# MK70F15WS register map
File version: 1.6
Registers are 32-bit, read-write, reset 0x0 unless marked. A register's access mark holds for its fields unless they carry their own. Offsets are from the block's base; [hi:lo] are bit positions; {n}, {i} and the like mark numbered series; 'fields as' and 'values as' point back to an identical list.

## CAU — Memory Mapped Cryptographic Acceleration Unit (MMCAU)
Base 0xE0081000
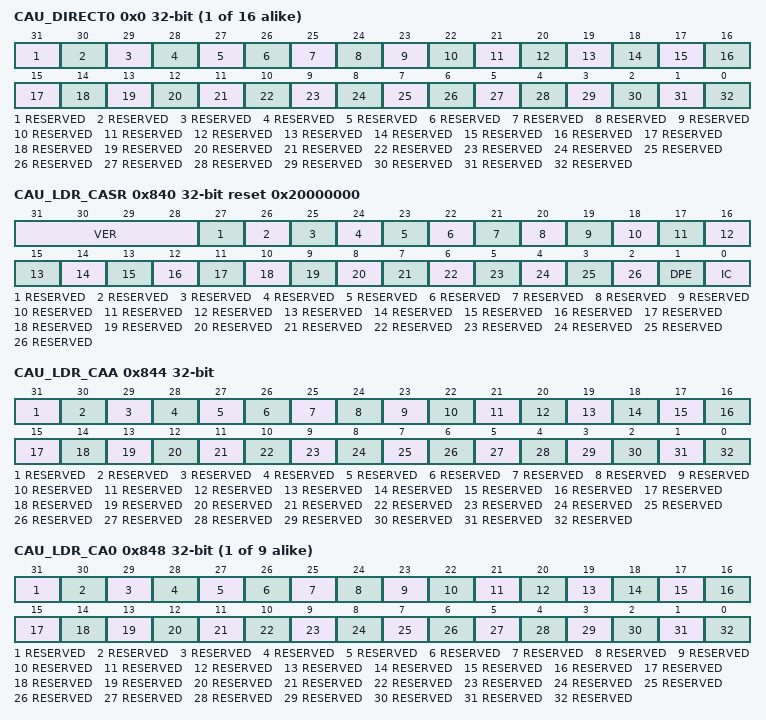
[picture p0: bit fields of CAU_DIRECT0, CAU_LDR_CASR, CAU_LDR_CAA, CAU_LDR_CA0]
{0x0+4i} CAU_DIRECT{i} wo (i=0..15) — Direct access register {i}
  [31] RESERVED, [30] RESERVED, [29] RESERVED, [28] RESERVED, [27] RESERVED, [26] RESERVED, [25] RESERVED, [24] RESERVED, [23] RESERVED, [22] RESERVED, [21] RESERVED, [20] RESERVED, [19] RESERVED, [18] RESERVED, [17] RESERVED, [16] RESERVED, [15] RESERVED, [14] RESERVED, [13] RESERVED, [12] RESERVED, [11] RESERVED, [10] RESERVED, [9] RESERVED, [8] RESERVED, [7] RESERVED, [6] RESERVED, [5] RESERVED, [4] RESERVED, [3] RESERVED, [2] RESERVED, [1] RESERVED, [0] RESERVED
0x840 CAU_LDR_CASR wo reset 0x20000000 — Status register - Load Register command
  [31:28] VER — CAU version
    1=Initial CAU version; 2=Second version, added support for SHA-256 algorithm.(This is the value on this device)
  [27] RESERVED
  [26] RESERVED
  [25] RESERVED
  [24] RESERVED
  [23] RESERVED
  [22] RESERVED
  [21] RESERVED
  [20] RESERVED
  [19] RESERVED
  [18] RESERVED
  [17] RESERVED
  [16] RESERVED
  [15] RESERVED
  [14] RESERVED
  [13] RESERVED
  [12] RESERVED
  [11] RESERVED
  [10] RESERVED
  [9] RESERVED
  [8] RESERVED
  [7] RESERVED
  [6] RESERVED
  [5] RESERVED
  [4] RESERVED
  [3] RESERVED
  [2] RESERVED
  [1] DPE
    0=No error detected; 1=DES key parity error detected
  [0] IC
    0=No illegal commands issued; 1=Illegal command issued
0x844 CAU_LDR_CAA wo — Accumulator register - Load Register command
  fields as CAU_DIRECT0
{0x848+4i} CAU_LDR_CA{i} wo (i=0..8) — General Purpose Register {i} - Load Register command
  fields as CAU_DIRECT0
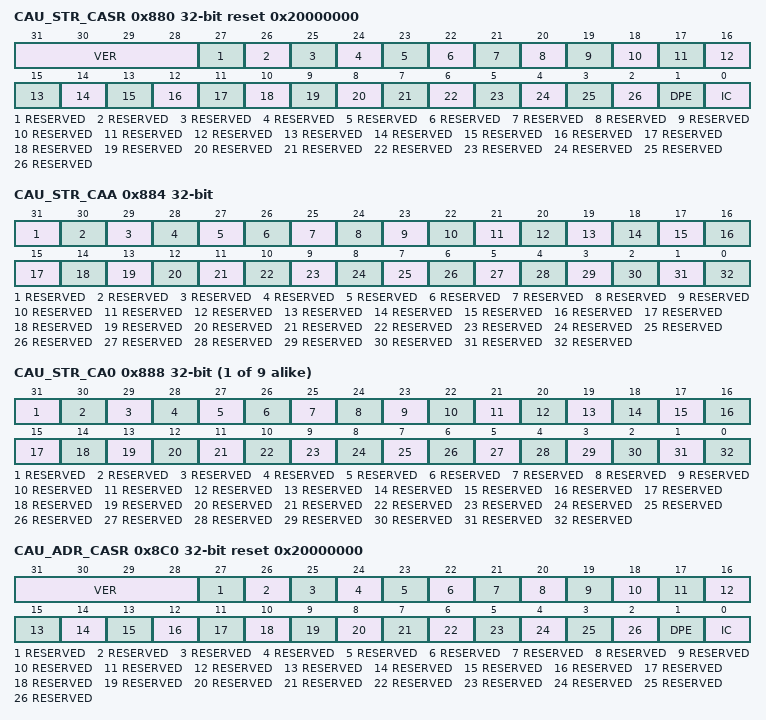
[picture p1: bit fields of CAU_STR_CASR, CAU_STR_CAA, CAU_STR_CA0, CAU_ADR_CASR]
0x880 CAU_STR_CASR ro reset 0x20000000 — Status register - Store Register command
  fields as CAU_LDR_CASR
0x884 CAU_STR_CAA ro — Accumulator register - Store Register command
  fields as CAU_DIRECT0
{0x888+4i} CAU_STR_CA{i} ro (i=0..8) — General Purpose Register {i} - Store Register command
  fields as CAU_DIRECT0
0x8C0 CAU_ADR_CASR wo reset 0x20000000 — Status register - Add Register command
  fields as CAU_LDR_CASR
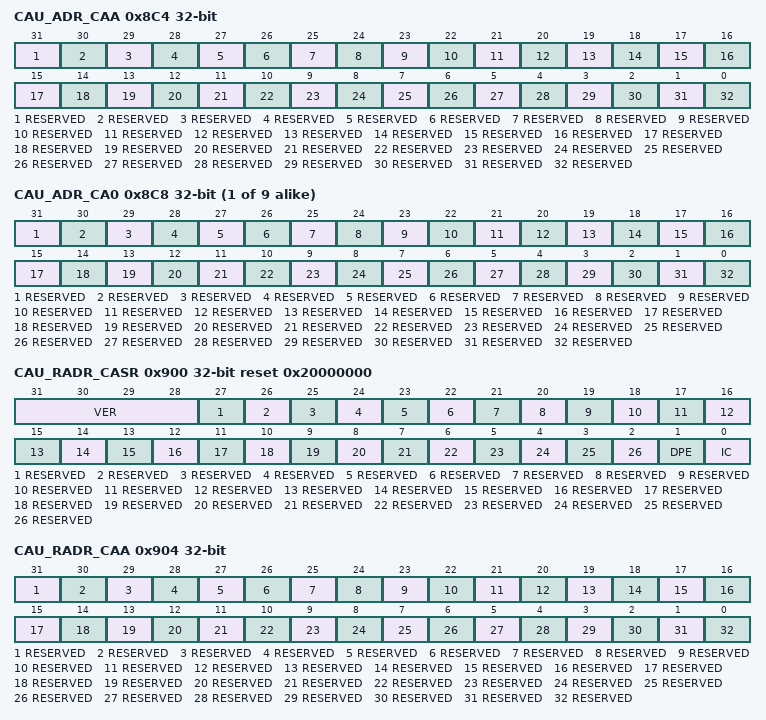
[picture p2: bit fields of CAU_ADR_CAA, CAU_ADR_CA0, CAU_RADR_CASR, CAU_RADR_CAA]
0x8C4 CAU_ADR_CAA wo — Accumulator register - Add to register command
  fields as CAU_DIRECT0
{0x8C8+4i} CAU_ADR_CA{i} wo (i=0..8) — General Purpose Register {i} - Add to register command
  fields as CAU_DIRECT0
0x900 CAU_RADR_CASR wo reset 0x20000000 — Status register - Reverse and Add to Register command
  fields as CAU_LDR_CASR
0x904 CAU_RADR_CAA wo — Accumulator register - Reverse and Add to Register command
  fields as CAU_DIRECT0
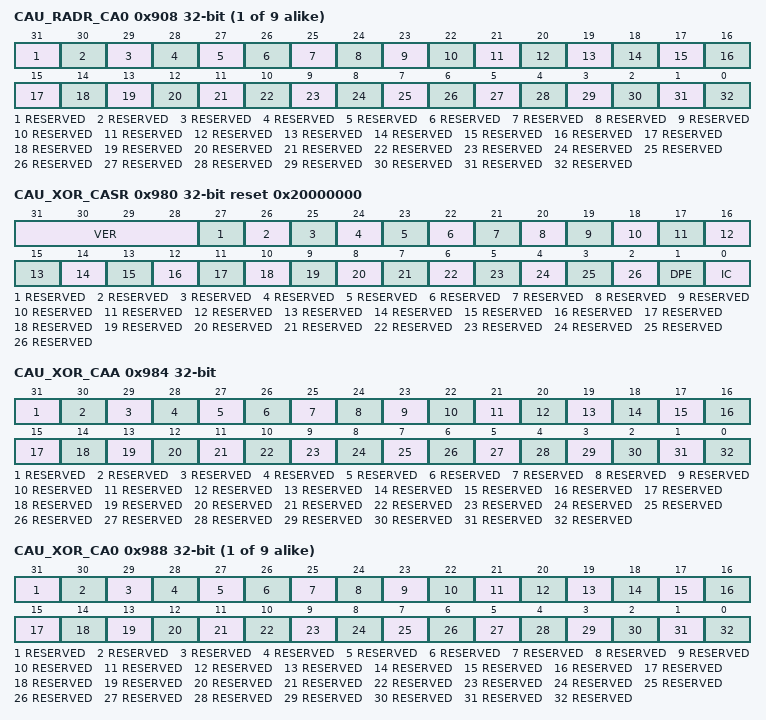
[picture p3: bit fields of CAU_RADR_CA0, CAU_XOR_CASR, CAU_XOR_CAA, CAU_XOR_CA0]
{0x908+4i} CAU_RADR_CA{i} wo (i=0..8) — General Purpose Register {i} - Reverse and Add to Register command
  fields as CAU_DIRECT0
0x980 CAU_XOR_CASR wo reset 0x20000000 — Status register - Exclusive Or command
  fields as CAU_LDR_CASR
0x984 CAU_XOR_CAA wo — Accumulator register - Exclusive Or command
  fields as CAU_DIRECT0
{0x988+4i} CAU_XOR_CA{i} wo (i=0..8) — General Purpose Register {i} - Exclusive Or command
  fields as CAU_DIRECT0
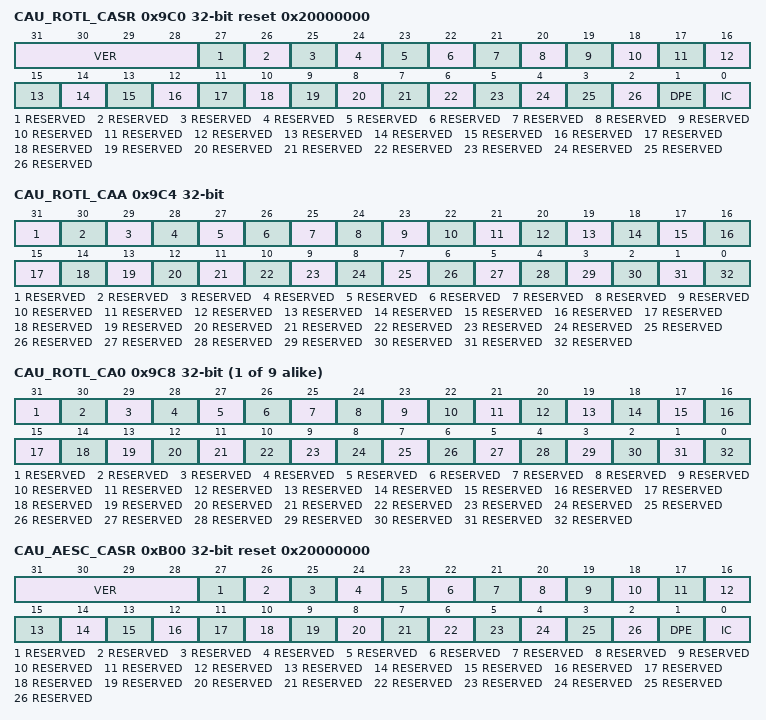
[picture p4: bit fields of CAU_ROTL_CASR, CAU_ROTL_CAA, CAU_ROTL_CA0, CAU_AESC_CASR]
0x9C0 CAU_ROTL_CASR wo reset 0x20000000 — Status register - Rotate Left command
  fields as CAU_LDR_CASR
0x9C4 CAU_ROTL_CAA wo — Accumulator register - Rotate Left command
  fields as CAU_DIRECT0
{0x9C8+4i} CAU_ROTL_CA{i} wo (i=0..8) — General Purpose Register {i} - Rotate Left command
  fields as CAU_DIRECT0
0xB00 CAU_AESC_CASR wo reset 0x20000000 — Status register - AES Column Operation command
  fields as CAU_LDR_CASR
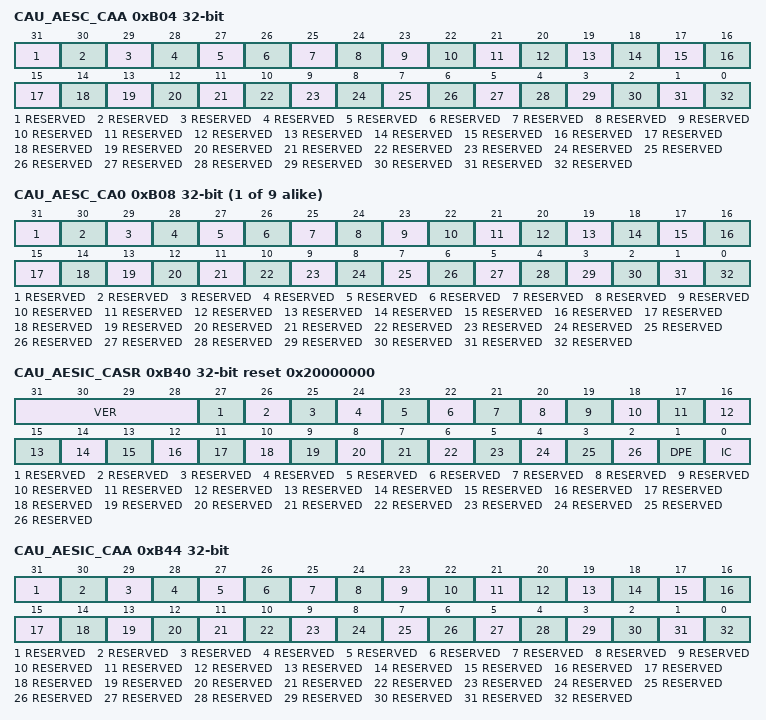
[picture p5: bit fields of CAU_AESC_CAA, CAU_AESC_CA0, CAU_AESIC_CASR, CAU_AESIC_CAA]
0xB04 CAU_AESC_CAA wo — Accumulator register - AES Column Operation command
  fields as CAU_DIRECT0
{0xB08+4i} CAU_AESC_CA{i} wo (i=0..8) — General Purpose Register {i} - AES Column Operation command
  fields as CAU_DIRECT0
0xB40 CAU_AESIC_CASR wo reset 0x20000000 — Status register - AES Inverse Column Operation command
  fields as CAU_LDR_CASR
0xB44 CAU_AESIC_CAA wo — Accumulator register - AES Inverse Column Operation command
  fields as CAU_DIRECT0
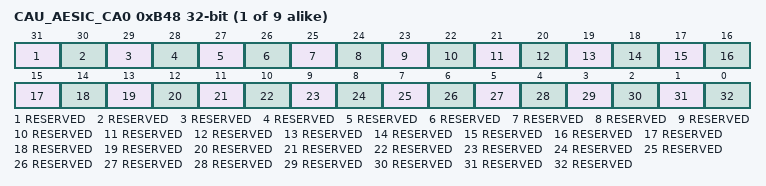
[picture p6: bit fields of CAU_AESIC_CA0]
{0xB48+4i} CAU_AESIC_CA{i} wo (i=0..8) — General Purpose Register {i} - AES Inverse Column Operation command
  fields as CAU_DIRECT0
